# PLL0_CFG register map
Vendor: Texas Instruments
Peripheral module from a debugger description file (folder J7ES).
Registers are 32-bit, read-write, reset 0x0 unless marked. A register's access mark holds for its fields unless they carry their own. Offsets are as the file gives them; lines under a group give offsets from that group; [hi:lo] are bit positions; {n}, {i} and the like mark numbered series; 'fields as' and 'values as' point back to an identical list; <NAME> marks a mode.

## PLL0_CFG
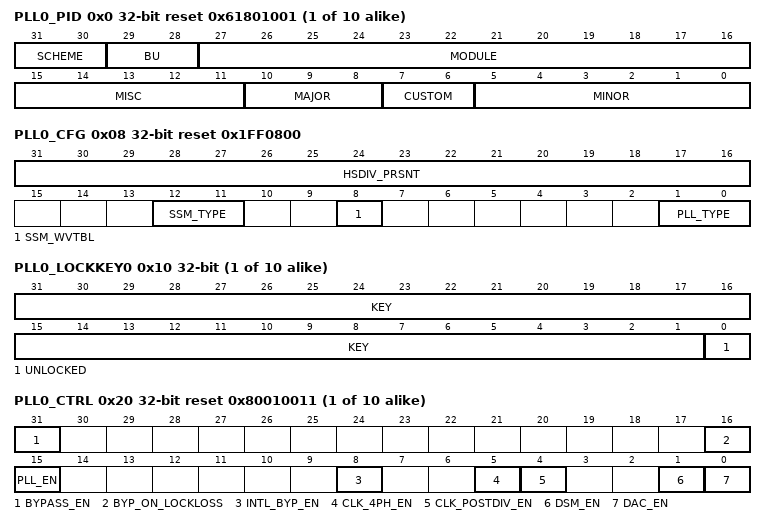
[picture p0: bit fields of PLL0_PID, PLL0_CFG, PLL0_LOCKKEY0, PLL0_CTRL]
{0x0+0x1000*i} PLL{i}_PID ro reset 0x61801001 (i=0..9) — Peripheral Identification Register
  [31:30] SCHEME — PID follows new scheme
  [29:28] BU — Business Unit - Processors
  [27:16] MODULE — Module functional identifier
  [15:11] MISC — Misc revision number
  [10:8] MAJOR — Major revision number
  [7:6] CUSTOM — custom revision number
  [5:0] MINOR — Minor revision number
0x08 PLL0_CFG access per field reset 0x1FF0800 — PLL Configuration
  [31:16] HSDIV_PRSNT ro — High Speed Divider Presence Each bit Indicates the presence of High Speed dividers 0-15.By definition HSDIV [4:0] are connected the PLL FOUTVCO output clock and HSDIV [15:5] are connected to the PLL FOUTPOSTDIV output clock
  [12:11] SSM_TYPE ro — Spread spectrum module presence Field values (Others are reserved):2'b00 - SSM is not present 2'b01 - SSM is present 2'b10 - Reserved 2'b11 - Reserved
  [8] SSM_WVTBL rw — Spread spectrum wave table presence1'b0 - SSM Wave table is not present 1'b1 - SSM Wave table is present
  [1:0] PLL_TYPE ro — Indicates PLL type Field values (Others are reserved):2'b00 - Fractional PLL 2'b01 - FractionalF PLL 2'b10 - De-Skew PLL
{0x10+0x1000*i} PLL{i}_LOCKKEY0 access per field (i=0..9)
  [31:1] KEY rw — Write the kick0 unlock value followed by the kick1 unlock value to unlock the write-protected Partition{i} registers
  [0] UNLOCKED ro — Unlock status.When set, indicates that the proper unlock sequence has been performed and the partition is unlocked for writing.
{0x14+0x1000*i} PLL{i}_LOCKKEY1 (i=0..9) — - PLL{i} Lock Key 1 RegisterAddr
  [31:0] LOCKKEY1_VAL — Write the kick1 unlock value after the kick0 unlock value to unlock the write-protected Partition{i} registers
{0x20+0x1000*i} PLL{i}_CTRL reset 0x80010011 (i=0..9) — - PLL{i} Control
  [31] BYPASS_EN — Bypass enable.This controls the glitch-free bypass mux. The BYPASS_EN bit should be set prior to making any changes to the PLL settings. 1'b0 - Synchronously select PLL and associated HSDIV clock outputs 1'b1 - Synchronously select the reference clock for all PLL and HSDIV clock outputs
  [16] BYP_ON_LOCKLOSS — Bypass on loss of PLL lock.This bit controls the PLL bypass mux to automatically switch the clock source to the reference clock when the PLL losses lock. 1'b0 - Do not automatically switch to ref clock source on PLL lock loss 1'b1 - Switch to ref clock source when PLL losses lock
  [15] PLL_EN — PLL enable1'b0 - PLL is disabled 1'b1 - PLL is enabled
  [8] INTL_BYP_EN — PLL internal bypass enable.This is an asynchronous mux which can produce glitches on the output clocks during switching. NOTE: Always program this bit field to 0.1'b0 - Output clocks are derived from the VCO clock 1'b1 - Output clocks are derived from the FREF reference clock
  [5] CLK_4PH_EN — Enable 4-phase clock generator.NOTE: Always program this bit to 0. This bit is ignored if CLK_POSTDIV_EN = 0 1'b0 - 4-phase dividers disabled. FOUT1PHx and FOUTn clocks are held low. 1'b1 - 4-phase dividers enabled. FOUT1PH0/90/180/270 and FOUT2, FOUT3, FOUT4 clocks are enabled.
  [4] CLK_POSTDIV_EN — Post divide CLK enable1'b0 - Post divide powered down. FOUTPOSTDIV and all auxiliary PLL clocks (4-ohase and synchronous divided clocks) are held low 1'b1 - Post divide enabled. FOUTPOSTDIV, 4-phase and synchronous clocks are enabled.
  [1] DSM_EN — Delta-Sigma modulator enable1'b0 - Delta-Sigma modulator is disabled 1'b1 - Delta-Sigma modulator is enabled
  [0] DAC_EN — Enable fractional noise canceling DAC This bit has no function when DSM_EN = 01'b0 - Fractional NC DAC is disabled 1'b1 - Fractional NC DAC is enabled
{0x24+0x1000*i} PLL{i}_STAT ro (i=0..9) — - PLL{i} Status
  [0] LOCK — PLL lock status.Software should wait for lock to be asserted before clearing the PLL_CTRL[31] BYPASS_EN bit 1'b0 - PLL is not locked 1'b1 - PLL is locked
{0x30+0x1000*i} PLL{i}_FREQ_CTRL0 reset 0x10 (i=0..8) — - PLL{i} Frequency Control {i} Register
  [11:0] FB_DIV_INT — PLL multiplier (integer portion) In Integer mode values of16 - 3200 (dec) are supported. In Fractional mode values of 20 to 320 are supported. 12'h000 - 12'h00F - Not supported12'h010 - Divide by 16 12'h011 - Divide by 17 ...12'h140 - Divide by 320 ...12'hC80 - Divide by 3200 12'hC81 - 12'hFFF - Not supported
{0x34+0x1000*i} PLL{i}_FREQ_CTRL1 (i=0..9) — - PLL0 Frequency Control 1 Register
  [23:0] FB_DIV_FRAC — PLL multiplier (fractional portion). Supports values of 0 to 0.999999940395.The total feedback divide value is (FB_DIV_INT + FB_DIV_FRAC / (2)) 24'h000000 - 0 24'h000001 - .000000059605 (1/(2)) 24'h000002 - .000000119209 (2/(2)) ... 24'h800000 - .500000000000... 24'hFFFFFF - .999999940395 (1677215/(2))
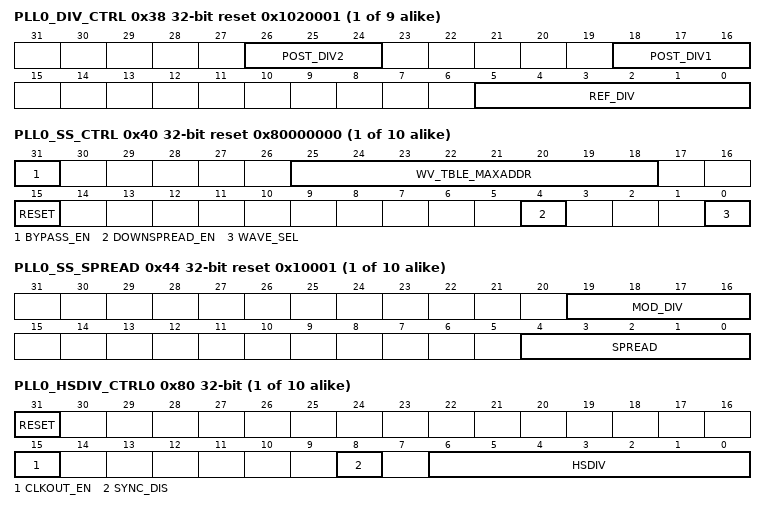
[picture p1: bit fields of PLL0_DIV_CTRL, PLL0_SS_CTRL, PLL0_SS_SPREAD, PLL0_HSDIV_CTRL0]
{0x38+0x1000*i} PLL{i}_DIV_CTRL reset 0x1020001 (i=0..8) — - PLL{i} Output Clock Divider Register
  [26:24] POST_DIV2 — Secondary post divider.Supports values of 1-7.
  [18:16] POST_DIV1 — Primary post divider.To ensure correct operation, POST_DIV1 must always be programmed to a value equal to or greater that POST_DIV2. Supports values of Supports values of 1-7 (Others are reserved): 3'b000 - Reserved 3'b001 - Divide by 1 3'b010 - Divide by 2 3'b011 - Divide by 3 3'b100 - Divide by 4 3'b101 - Divide by 5 3'b110 - Divide by 6 3'b111 - Divide by 7
  [5:0] REF_DIV — Reference clock pre-divider.Supports values of 1-63 6'b000000 - Reserved 6'b000001 - Divide by 1 6'b000010 - Divide by 2...6'b111111 - Divide by 63
{0x40+0x1000*i} PLL{i}_SS_CTRL reset 0x80000000 (i=0..9) — PLL_SS_CTRL register for pll{i}
  [31] BYPASS_EN — Bypass the SS modulator.1'b0 - Spread spectrum modulation is enabled 1'b1 - SSMOD is bypassed. No modulation of PLL frequency
  [25:18] WV_TBLE_MAXADDR — Wave table max address.Indicates the maximum number of address bits used to access the external wave table. These bits are not used if PLLn_CFG[8] SSM_WVTBL = 0
  [15] RESET — HSDIV reset.When set to 1 the SSM modulator is in reset
  [4] DOWNSPREAD_EN — Selects center spread or down spread clock variance1'b0 - Center spread 1'b1 - Down spread
  [0] WAVE_SEL — Wave pattern select External wave table should only be selected if PLLn_CFG[8] SSM_WVTBL = 1 Field values (Others are reserved):1'b0 - Use 128 point triangle wave table 1'b1 - Use external wave table
{0x44+0x1000*i} PLL{i}_SS_SPREAD reset 0x10001 (i=0..9) — PLL_SS_SPREAD register for pll{i}
  [19:16] MOD_DIV — Input clock divider.This divider sets the modulation frequency. Supports divide values of 1-63:6'b000000 - Reserved 6'b000001 - Divide by 1 6'b000010 - Divide by 2 ... 6'b111111 - Divide by 63
  [4:0] SPREAD — Sets the spread modulation depth.The depth is spread*0.1% 5'b00000 - Reserved (don't use) 5'b00001 - 0.1% 5'b00010 - 0.2%...5'b10000 - 1.6%...5'b11111 - 3.1%
{0x80+0x1000*i} PLL{i}_HSDIV_CTRL0 (i=0..9) — HSDIV_CTRL0 register for pll{i}
  [31] RESET — HSDIV reset.When set to 1 HSDIV is in reset
  [15] CLKOUT_EN — CLKOUT1 enable1'b0 - Synchronously disable CLKOUT1 1'b1 - Synchronously enable CLKOUT1
  [8] SYNC_DIS — Disable divider synchronization logic1'b0 - Changes to DIV value synchronized to prevent glitches 1'b1 - Changes are asynchronous
  [6:0] HSDIV — CLKOUT0 divider value (HSDIV1+1) Allowed values are0-127
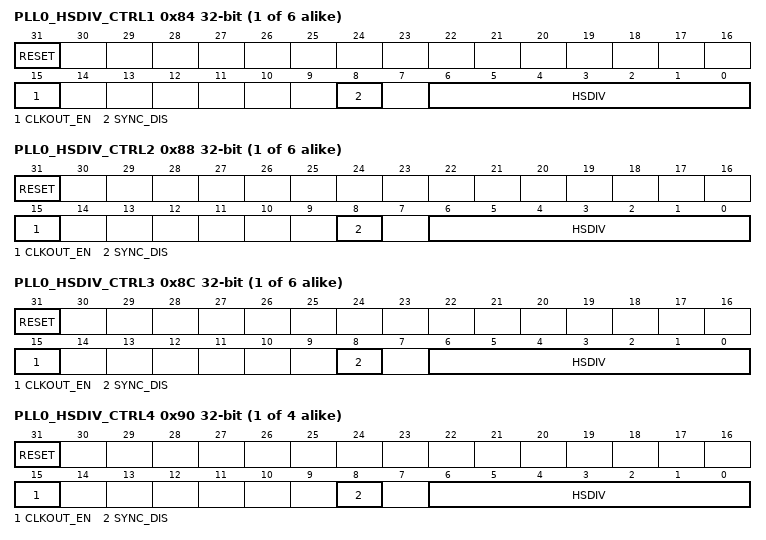
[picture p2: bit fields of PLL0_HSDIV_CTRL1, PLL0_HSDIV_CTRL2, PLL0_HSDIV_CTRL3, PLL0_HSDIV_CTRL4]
{0x84+0x1000*i} PLL{i}_HSDIV_CTRL1 (i=0..5) — HSDIV_CTRL1 register for pll{i}
  fields as PLL0_HSDIV_CTRL0
{0x88+0x1000*i} PLL{i}_HSDIV_CTRL2 (i=0..5) — HSDIV_CTRL2 register for pll{i}
  fields as PLL0_HSDIV_CTRL0
{0x8C+0x1000*i} PLL{i}_HSDIV_CTRL3 (i=0..5) — HSDIV_CTRL3 register for pll{i}
  fields as PLL0_HSDIV_CTRL0
{0x90+0x1000*i} PLL{i}_HSDIV_CTRL4 (i=0..3) — HSDIV_CTRL4 register for pll{i}
  fields as PLL0_HSDIV_CTRL0
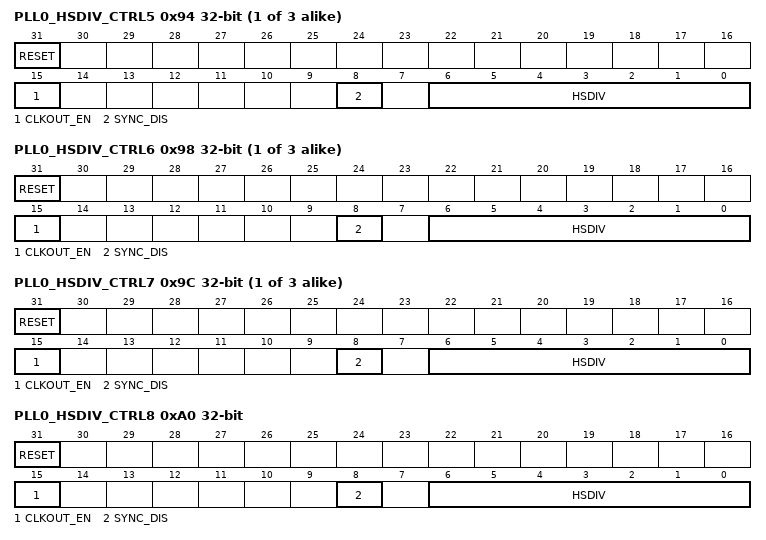
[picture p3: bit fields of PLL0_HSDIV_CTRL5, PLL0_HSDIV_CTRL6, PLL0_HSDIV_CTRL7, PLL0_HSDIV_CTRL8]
{0x94+0x1000*i} PLL{i}_HSDIV_CTRL5 (i=0..2) — HSDIV_CTRL5 register for pll{i}
  fields as PLL0_HSDIV_CTRL0
{0x98+0x1000*i} PLL{i}_HSDIV_CTRL6 (i=0..2) — HSDIV_CTRL6 register for pll{i}
  fields as PLL0_HSDIV_CTRL0
{0x9C+0x1000*i} PLL{i}_HSDIV_CTRL7 (i=0..2) — HSDIV_CTRL7 register for pll{i}
  fields as PLL0_HSDIV_CTRL0
0xA0 PLL0_HSDIV_CTRL8 — HSDIV_CTRL8 register for pll0
  fields as PLL0_HSDIV_CTRL0
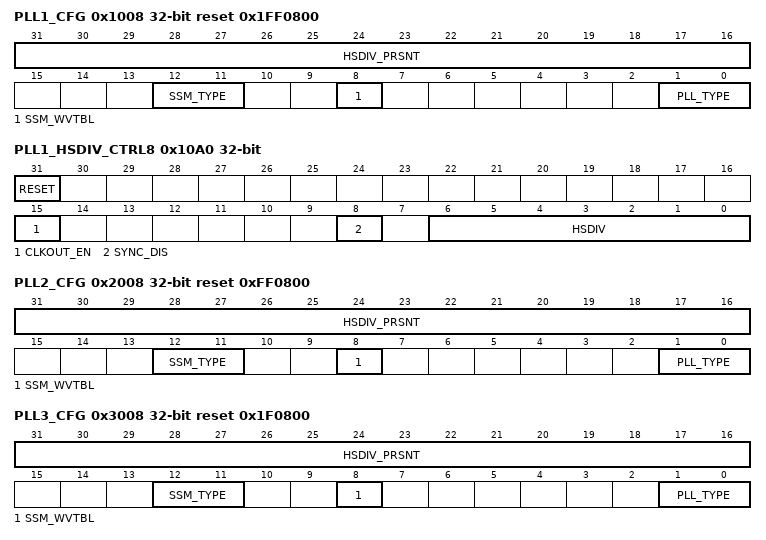
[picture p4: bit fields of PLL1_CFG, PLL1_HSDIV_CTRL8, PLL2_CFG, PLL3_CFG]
0x1008 PLL1_CFG access per field reset 0x1FF0800 — PLL Configuration
  fields as PLL0_CFG
0x10A0 PLL1_HSDIV_CTRL8 — HSDIV_CTRL8 register for pll1
  fields as PLL0_HSDIV_CTRL0
0x2008 PLL2_CFG access per field reset 0xFF0800 — PLL Configuration
  fields as PLL0_CFG
0x3008 PLL3_CFG access per field reset 0x1F0800 — PLL Configuration
  fields as PLL0_CFG
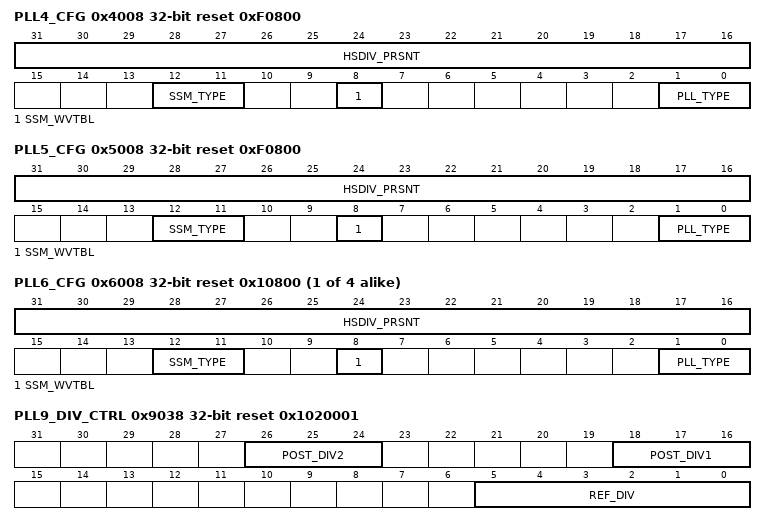
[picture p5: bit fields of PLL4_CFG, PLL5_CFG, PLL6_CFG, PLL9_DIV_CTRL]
0x4008 PLL4_CFG access per field reset 0xF0800 — PLL Configuration
  fields as PLL0_CFG
0x5008 PLL5_CFG access per field reset 0xF0800 — PLL Configuration
  fields as PLL0_CFG
{0x8+0x1000*i} PLL{i}_CFG access per field reset 0x10800 (i=6..9) — PLL Configuration
  fields as PLL0_CFG
0x9030 PLL9_FREQ_CTRL0 reset 0x10 — - PLL9 Frequency Control 9 Register
  [11:0] FB_DIV_INT — PLL multiplier (integer portion) In Integer mode values of16 - 3200 (dec) are supported. In Fractional mode values of 20 to 320 are supported.12'h000 - 12'h00F - Not supported 12'h010 - Divide by 16 12'h011 - Divide by 17 ...12'h140 - Divide by 320 ...12'hC80 - Divide by 3200 12'hC81 - 12'hFFF - Not supported
0x9038 PLL9_DIV_CTRL reset 0x1020001 — - PLL9 Output Clock Divider Register
  [26:24] POST_DIV2 — Secondary post divider.Supports values of 1-7.
  [18:16] POST_DIV1 — Primary post divider.To ensure correct operation, POST_DIV1 must always be programmed to a value equal to or greater that POST_DIV2. Supports values of Supports values of 1-7 (Others are reserved): 3'b000 - Reserved 3'b001 - Divide by 1 3'b010 - Divide by 2 3'b011 - Divide by 3 3'b100 - Divide by 4 3'b101 - Divide by 5 3'b110 - Divide by 6 3'b111 - Divide by 7
  [5:0] REF_DIV — Reference clock pre-divider.Supports values of 1-63 6'b000000 - Reserved 6'b000001 - Divide by 1 6'b000010 - Divide by 2...6'b111111 - Divide by 633
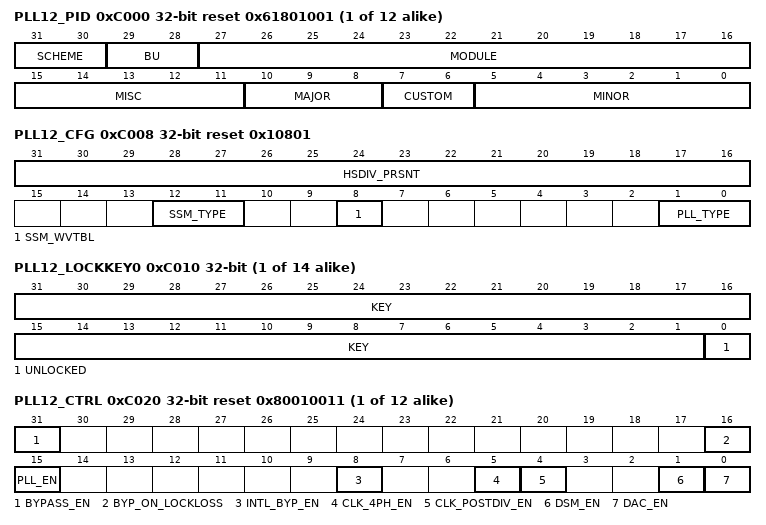
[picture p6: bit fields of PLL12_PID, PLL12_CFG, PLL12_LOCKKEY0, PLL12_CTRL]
{0x0+0x1000*i} PLL{i}_PID ro reset 0x61801001 (i=12..23) — Peripheral Identification Register
  fields as PLL0_PID
0xC008 PLL12_CFG access per field reset 0x10801 — PLL Configuration
  fields as PLL0_CFG
{0x10+0x1000*i} PLL{i}_LOCKKEY0 access per field (i=12..25)
  fields as PLL0_LOCKKEY0
{0x14+0x1000*i} PLL{i}_LOCKKEY1 (i=12..23) — - PLL{i} Lock Key 1 RegisterAddr
  fields as PLL0_LOCKKEY1
{0x20+0x1000*i} PLL{i}_CTRL reset 0x80010011 (i=12..23) — - PLL{i} Control
  fields as PLL0_CTRL
{0x24+0x1000*i} PLL{i}_STAT ro (i=12..23) — - PLL{i} Status
  fields as PLL0_STAT
0xC030 PLL12_FREQ_CTRL0 reset 0x10 — - PLL12 Frequency Control 12 Register
  fields as PLL0_FREQ_CTRL0
{0x34+0x1000*i} PLL{i}_FREQ_CTRL1 (i=12..23) — - PLL0 Frequency Control 1 Register
  fields as PLL0_FREQ_CTRL1
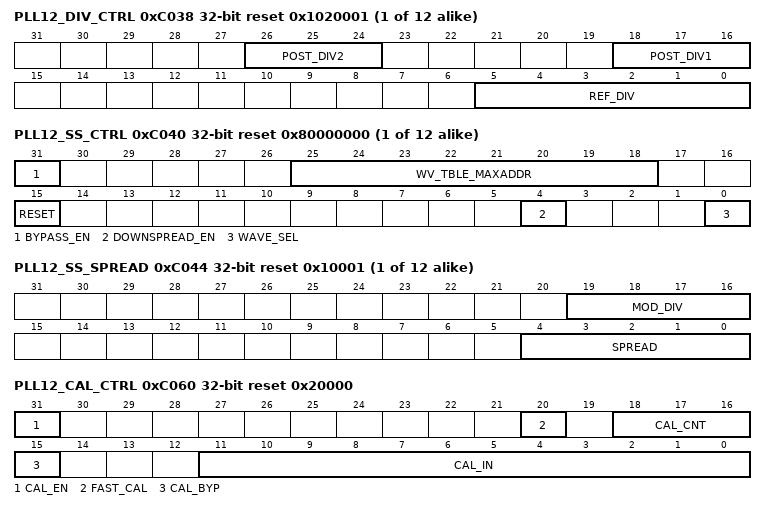
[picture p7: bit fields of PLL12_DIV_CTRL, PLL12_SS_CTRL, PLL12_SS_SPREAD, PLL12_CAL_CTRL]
{0x38+0x1000*i} PLL{i}_DIV_CTRL reset 0x1020001 (i=12..23) — - PLL{i} Output Clock Divider Register
  fields as PLL0_DIV_CTRL
{0x40+0x1000*i} PLL{i}_SS_CTRL reset 0x80000000 (i=12..23) — PLL_SS_CTRL register for pll{i}
  fields as PLL0_SS_CTRL
{0x44+0x1000*i} PLL{i}_SS_SPREAD reset 0x10001 (i=12..23) — PLL_SS_SPREAD register for pll{i}
  fields as PLL0_SS_SPREAD
0xC060 PLL12_CAL_CTRL reset 0x20000 — - PLL12 Calibration Control Register
  [31] CAL_EN — Calibration enable to actively adjust for input skew1'b0 - Disabled. Static phase offset determined by analog matching only 1'b1 - Enabled. Static phase offset adjusted by phase sensing at input
  [20] FAST_CAL — Fast calibration enabled1'b0 - Normal operation 1'b1 - Used for initial calibration if initial value is not already known
  [18:16] CAL_CNT — Calibration loop programmable counter.Selects the number of PFD edges to wait after each calibration step defined by 2**cal_cnt
  [15] CAL_BYP — Calibration bypass1'b0 - Use the calibration output to set the phase correction 1'b1 - Use the cal_in input value to set the phase correction
  [11:0] CAL_IN — Calibration input When cal_byp is 1'b0, this represents the initial condition for calibration.When cal_byp is 1'b1, this is the override value for calibration. Value is a signed integer with positive values delaying the faster path reset and negative values delaying the slower path reset.
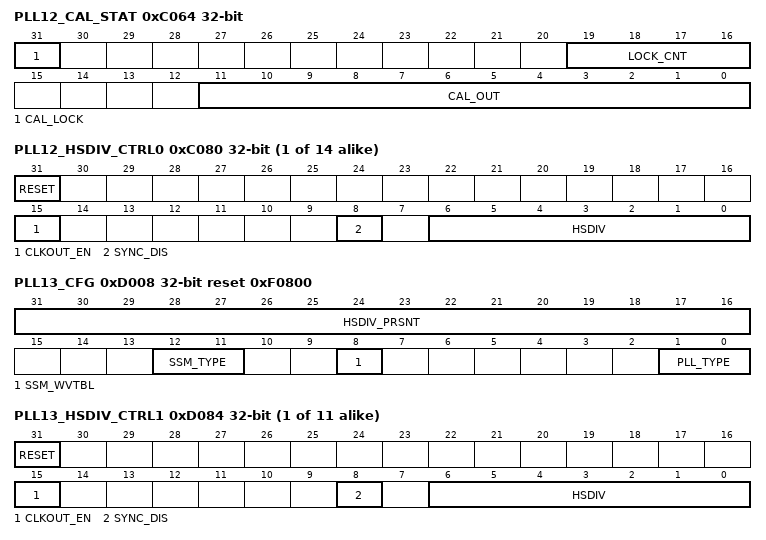
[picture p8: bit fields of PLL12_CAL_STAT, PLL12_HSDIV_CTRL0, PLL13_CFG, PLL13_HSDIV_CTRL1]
0xC064 PLL12_CAL_STAT ro — - PLL12 Calibration Status Register
  [31] CAL_LOCK — Reserved for future use
  [19:16] LOCK_CNT — Reserved for future use
  [11:0] CAL_OUT — Output of the calibration block if cal_byp = 1'b0.If cal_byp = 1'b1 it is a buffer version of cal_in[11:0]. Can be used to read the phase calibration state to for later use as an override value to bypass skew calibration
{0x80+0x1000*i} PLL{i}_HSDIV_CTRL0 (i=12..25) — HSDIV_CTRL0 register for pll{i}
  fields as PLL0_HSDIV_CTRL0
0xD008 PLL13_CFG access per field reset 0xF0800 — PLL Configuration
  fields as PLL0_CFG
0xD030 PLL13_FREQ_CTRL0 reset 0x10 — - PLL13 Frequency Control 13 Register
  fields as PLL9_FREQ_CTRL0
{0x84+0x1000*i} PLL{i}_HSDIV_CTRL1 (i=13..23) — HSDIV_CTRL1 register for pll{i}
  fields as PLL0_HSDIV_CTRL0
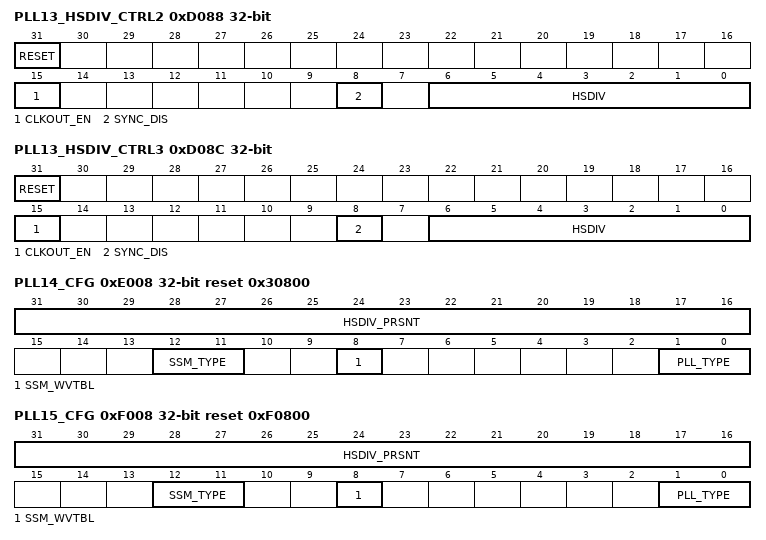
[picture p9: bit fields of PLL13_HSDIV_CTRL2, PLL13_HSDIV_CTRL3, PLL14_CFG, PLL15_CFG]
0xD088 PLL13_HSDIV_CTRL2 — HSDIV_CTRL2 register for pll13
  fields as PLL0_HSDIV_CTRL0
0xD08C PLL13_HSDIV_CTRL3 — HSDIV_CTRL3 register for pll13
  fields as PLL0_HSDIV_CTRL0
0xE008 PLL14_CFG access per field reset 0x30800 — PLL Configuration
  fields as PLL0_CFG
{0x30+0x1000*i} PLL{i}_FREQ_CTRL0 reset 0x10 (i=14..23) — - PLL{i} Frequency Control {i} Register
  fields as PLL0_FREQ_CTRL0
0xF008 PLL15_CFG access per field reset 0xF0800 — PLL Configuration
  fields as PLL0_CFG
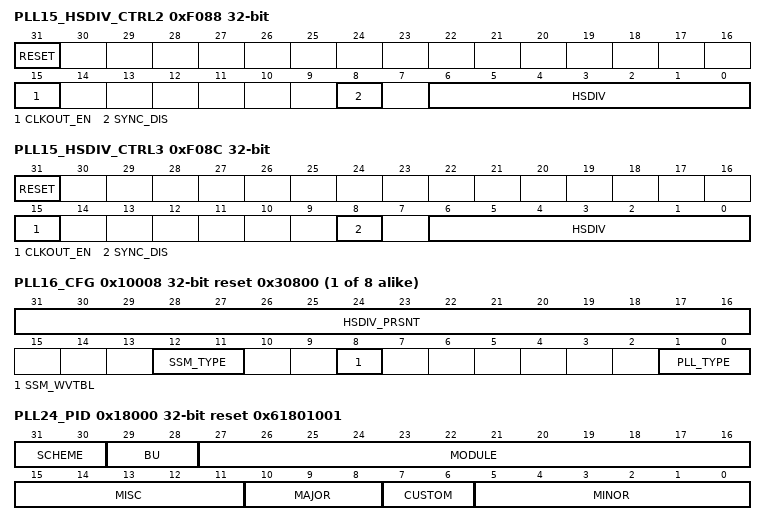
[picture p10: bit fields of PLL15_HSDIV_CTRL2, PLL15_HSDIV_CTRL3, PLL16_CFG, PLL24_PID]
0xF088 PLL15_HSDIV_CTRL2 — HSDIV_CTRL2 register for pll15
  fields as PLL0_HSDIV_CTRL0
0xF08C PLL15_HSDIV_CTRL3 — HSDIV_CTRL3 register for pll15
  fields as PLL0_HSDIV_CTRL0
{0x8+0x1000*i} PLL{i}_CFG access per field reset 0x30800 (i=16..23) — PLL Configuration
  fields as PLL0_CFG
0x18000 PLL24_PID ro reset 0x61801001
  fields as PLL0_PID
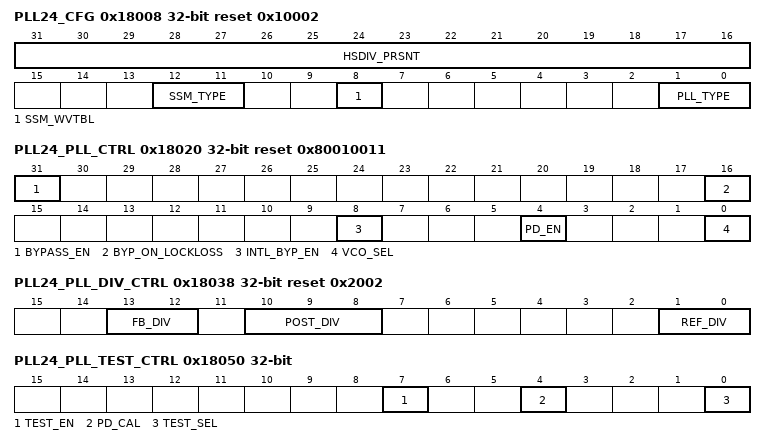
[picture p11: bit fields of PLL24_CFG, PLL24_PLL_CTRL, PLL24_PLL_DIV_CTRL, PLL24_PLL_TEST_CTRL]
0x18008 PLL24_CFG access per field reset 0x10002 — PLL Configuration
  fields as PLL0_CFG
0x18014 PLL24_LOCKKEY1 — LOCK register - LOCKKEY1 component
  [31:0] LOCKKEY1_VAL — Write the kick1 unlock value after the kick0 unlock value to unlock the write-protected Partition24 registers
0x18020 PLL24_PLL_CTRL reset 0x80010011 — PLL_CTRL register for pll24
  [31] BYPASS_EN — Bypass enable.This controls the glitch-free bypass mux. The BYPASS_EN bit should be set prior to making any changes to the PLL settings. 1'b0 - Synchronously select PLL clock outputs 1'b1 - Synchronously select the reference clock for all PLL cock outputs
  [16] BYP_ON_LOCKLOSS — Bypass on loss of PLL lock.This bit controls the PLL bypass mux to automatically switch the clock source to the reference clock when the PLL losses lock. 1'b0 - Do not automatically switch to ref clock source on PLL lock loss 1'b1 - Switch to ref clock source when PLL losses lock
  [8] INTL_BYP_EN — PLL internal bypass enable.This is an asynchronous mux which can produce glitches on the output clocks during switching. NOTE: Always program this bit field to 0.1'b0 - Output clocks are derived from the VCO clock 1'b1 - Output clocks are derived from the FREF reference clock
  [4] PD_EN — Power down.When set to 1, deskew PLL is powered down
  [0] VCO_SEL — Select clock source for post divider1'b0 - Use VCOCLK /2NOTE: VCO_SEL bit does not affect FOUT1X output used in this family of devices.
0x18024 PLL24_DSPLL_STAT ro — DSPLL_STAT register for pll24
  fields as PLL0_STAT
0x18038 PLL24_PLL_DIV_CTRL reset 0x2002 — PLL_DIV_CTRL register for pll24
  [13:12] FB_DIV — Feedback divide value:2'b00 – Divide by 4 2'b01 – Divide by 2 2'b10 – Divide by 1 2'b11 – Divide by 1
  [10:8] POST_DIV — Post divide value:3'b000 – Divided by 1 3'b001 – Divided by 2 3'b010 – Divided by 4 3'b011– Divided by 8 3'b100 – Divided by 16 3'b101 – Divided by 32 3'b110 – Divided by 64 3'b111 – Divided by 128
  [1:0] REF_DIV — Reference divide value:2'b00 – Divide by 4 2'b01 – Divide by 2 2'b10 – Divide by 1 2'b11 – Divide by 1
0x18050 PLL24_PLL_TEST_CTRL — PLL_TEST_CTRL register for pll24
  [7] TEST_EN — Enable test mux output1'b0 - TESTOUT is held low 1'b1 - TESTOUT is CKFB or FREF based on test_sel bit
  [4] PD_CAL — Skew calibration power down. This bit is for test purposes only.1'b0 - Skew calibration is not powered down1'b1 - Skew calibration is powered down
  [0] TEST_SEL — Selects TESTOUT clock source1'b0 - CKFB 1'b1 - FREF
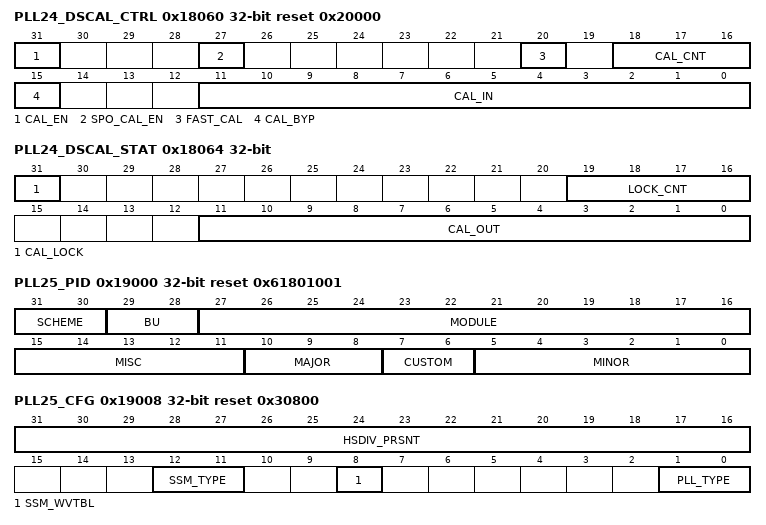
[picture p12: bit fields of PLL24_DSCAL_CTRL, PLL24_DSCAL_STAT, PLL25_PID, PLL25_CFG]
0x18060 PLL24_DSCAL_CTRL reset 0x20000 — DSCAL_CTRL register for pll24
  [31] CAL_EN — Calibration enable to actively adjust for input skew1'b0 - Disabled. Static phase offset determined by analog matching only 1'b1 - Enabled. Static phase offset adjusted by phase sensing at input
  [27] SPO_CAL_EN — Enable the SPO_CAL_CLKOUT when set
  [20] FAST_CAL — Fast calibration enabled1'b0 - Normal operation 1'b1 - Used for initial calibration if initial value is not already known
  [18:16] CAL_CNT — Calibration loop programmable counter.Selects the number of PFD edges to wait after each calibration step defined by 2**cal_cnt
  [15] CAL_BYP — Calibration bypass1'b0 - Use the calibration output to set the phase correction 1'b1 - Use the cal_in input value to set the phase correction
  [11:0] CAL_IN — Calibration input When cal_byp is 1'b0, this represents the initial condition for calibration.When cal_byp is 1'b1, this is the override value for calibration. Value is a signed integer with positive values delaying the faster path reset and negative values delaying the slower path reset.
0x18064 PLL24_DSCAL_STAT ro — DSCAL_STAT register for pll24
  [31] CAL_LOCK — Reserved for future use
  [19:16] LOCK_CNT — Reserved for future use
  [11:0] CAL_OUT — Output of the calibration block if cal_byp = 1'b0.If cal_byp = 1'b1 it is a buffer version of cal_in[11:0]. Can be used to read the phase calibration state to for later use as an override value to bypass skew calibration.
0x19000 PLL25_PID ro reset 0x61801001 — Peripheral Identification Register
  fields as PLL0_PID
0x19008 PLL25_CFG access per field reset 0x30800 — PLL Configuration
  fields as PLL0_CFG
0x19014 PLL25_LOCKKEY1 — - PLL25 Lock Key 1 RegisterAddr
  [31:0] LOCKKEY1_VAL — Write the kick1 unlock value after the kick0 unlock value to unlock the write-protected Partition25 registers
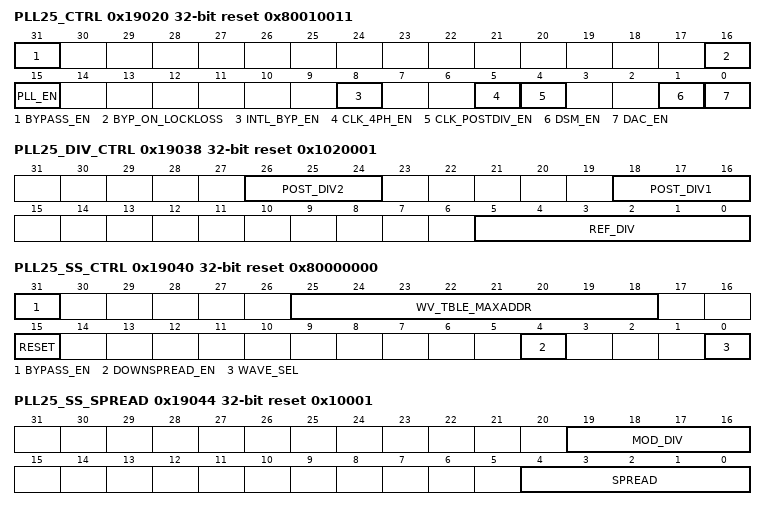
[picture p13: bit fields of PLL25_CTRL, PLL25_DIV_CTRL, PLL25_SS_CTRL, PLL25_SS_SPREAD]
0x19020 PLL25_CTRL reset 0x80010011 — - PLL25 Control
  fields as PLL0_CTRL
0x19024 PLL25_STAT ro — - PLL25 Status
  fields as PLL0_STAT
0x19030 PLL25_FREQ_CTRL0 reset 0x10 — - PLL25 Frequency Control 25 Register
  fields as PLL0_FREQ_CTRL0
0x19034 PLL25_FREQ_CTRL1 — - PLL0 Frequency Control 1 Register
  fields as PLL0_FREQ_CTRL1
0x19038 PLL25_DIV_CTRL reset 0x1020001 — - PLL25 Output Clock Divider Register
  fields as PLL0_DIV_CTRL
0x19040 PLL25_SS_CTRL reset 0x80000000 — PLL_SS_CTRL register for pll25
  fields as PLL0_SS_CTRL
0x19044 PLL25_SS_SPREAD reset 0x10001 — PLL_SS_SPREAD register for pll25
  fields as PLL0_SS_SPREAD
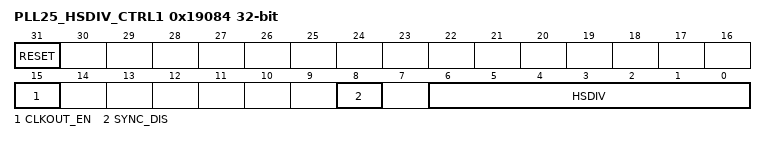
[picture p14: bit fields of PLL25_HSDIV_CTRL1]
0x19084 PLL25_HSDIV_CTRL1 — HSDIV_CTRL1 register for pll25
  fields as PLL0_HSDIV_CTRL0
